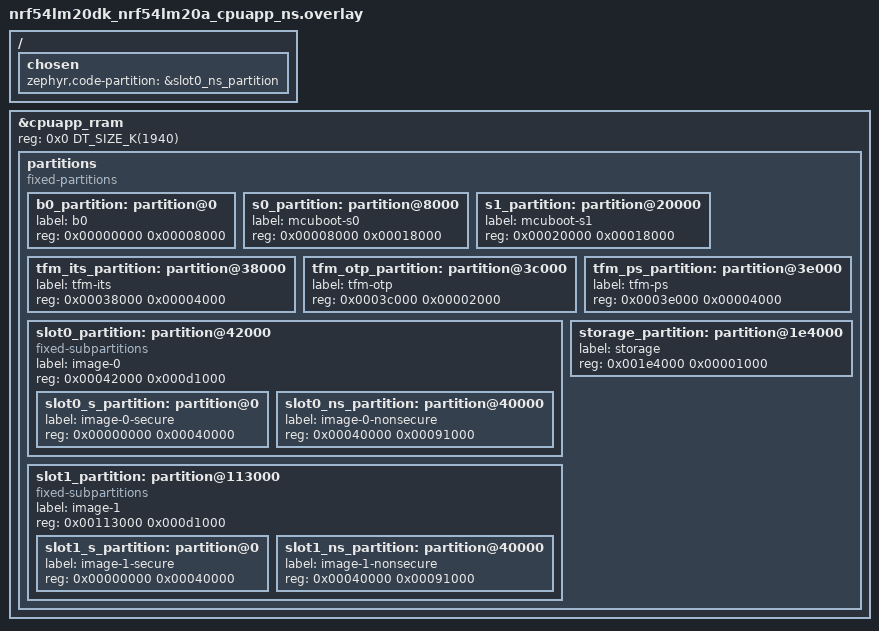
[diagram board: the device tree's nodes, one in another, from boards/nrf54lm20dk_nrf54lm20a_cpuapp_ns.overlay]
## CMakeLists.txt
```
cmake_minimum_required(VERSION 3.20.0)

find_package(Zephyr REQUIRED HINTS $ENV{ZEPHYR_BASE})
project(smp_svr)

target_sources(app PRIVATE src/main.c)
target_sources(app PRIVATE src/bluetooth.c)
```

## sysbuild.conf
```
# Enable an upgradable MCUboot chain:
# NSIB (B0) verifies and boots MCUboot, then MCUboot verifies the application.
SB_CONFIG_PARTITION_MANAGER=n
SB_CONFIG_SECURE_BOOT_APPCORE=y
SB_CONFIG_BOOTLOADER_MCUBOOT=y

# nRF54L/LM devices use Ed25519 for secure boot and MCUboot signatures.
SB_CONFIG_BOOT_SIGNATURE_TYPE_ED25519=y
SB_CONFIG_SECURE_BOOT_SIGNING_KEY_FILE="\${ZEPHYR_MCUBOOT_MODULE_DIR}/root-ed25519.pem"
SB_CONFIG_BOOT_SIGNATURE_KEY_FILE="\${ZEPHYR_MCUBOOT_MODULE_DIR}/root-ed25519.pem"

# The NSIB/B0 verification key is provisioned into KMU by the custom sysbuild
# keyfile generation step in sysbuild/CMakeLists.txt. MCUboot's application
# verification key is compiled into MCUboot to keep provisioning simple.
SB_CONFIG_SECURE_BOOT_MCUBOOT_VERSION="0.0.1+2"
```

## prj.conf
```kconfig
# Minimal BLE SMP DFU application for nRF54LM20A.
# For the /ns target, TF-M is built automatically. Keep the default profile so
# the static DTS layout can provide an aligned secure/non-secure flash layout.
CONFIG_USE_DT_CODE_PARTITION=y

CONFIG_NET_BUF=y
CONFIG_ZCBOR=y
CONFIG_CRC=y
CONFIG_MCUMGR=y
CONFIG_STREAM_FLASH=y
CONFIG_FLASH_MAP=y
CONFIG_FLASH=y

# MCUboot application update support.
CONFIG_BOOTLOADER_MCUBOOT=y
CONFIG_IMG_MANAGER=y
CONFIG_MCUMGR_GRP_IMG=y
CONFIG_MCUMGR_GRP_OS=y

# Application image version used by MCUboot and printed at boot.
CONFIG_MCUBOOT_IMGTOOL_SIGN_VERSION="1.0.2+4"
CONFIG_MCUBOOT_EXTRA_IMGTOOL_ARGS="--slot-size 0xd1000 --hex-addr 0x42000"

CONFIG_BT_DEVICE_NAME="NCS_DFU_LM20A"

# Stack sizes for Bluetooth SMP DFU requests.
CONFIG_SYSTEM_WORKQUEUE_STACK_SIZE=2304
CONFIG_MAIN_STACK_SIZE=2176

# Logging.
CONFIG_LOG=y
CONFIG_MCUBOOT_UTIL_LOG_LEVEL_WRN=y
CONFIG_LOG_MAX_LEVEL=3
```

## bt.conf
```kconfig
CONFIG_BT=y
CONFIG_BT_PERIPHERAL=y
CONFIG_BT_DEVICE_NAME="NCS_DFU_LM20A"

# Large ATT packets improve Bluetooth SMP DFU throughput.
CONFIG_BT_L2CAP_TX_MTU=498
CONFIG_BT_BUF_ACL_RX_SIZE=502
CONFIG_BT_BUF_ACL_TX_SIZE=502
CONFIG_BT_CTLR_DATA_LENGTH_MAX=251
CONFIG_BT_CTLR_PHY_2M=y

# Bluetooth SMP transport.
CONFIG_MCUMGR_TRANSPORT_BT=y
CONFIG_MCUMGR_TRANSPORT_BT_CONN_PARAM_CONTROL=y

# MCUmgr buffer size is optimized to fit one SMP packet divided into five Bluetooth Write Commands,
# transmitted with the maximum possible MTU value: 498 bytes.
CONFIG_MCUMGR_TRANSPORT_BT_REASSEMBLY=y
CONFIG_MCUMGR_TRANSPORT_NETBUF_SIZE=2475
CONFIG_MCUMGR_GRP_OS_MCUMGR_PARAMS=y
CONFIG_MCUMGR_TRANSPORT_WORKQUEUE_STACK_SIZE=4608

# Keep the controller configuration small.
CONFIG_BT_CTLR_LE_PING=n
```

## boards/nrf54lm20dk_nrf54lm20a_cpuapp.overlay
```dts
/*
 * Static DTS partitions for nRF54LM20A with NSIB + upgradable MCUboot.
 */

/delete-node/ &boot_partition;
/delete-node/ &slot0_partition;
/delete-node/ &slot1_partition;
/delete-node/ &storage_partition;

&cpuapp_rram {
	reg = <0x0 DT_SIZE_K(1940)>;

	partitions {
		compatible = "fixed-partitions";
		#address-cells = <1>;
		#size-cells = <1>;

		b0_partition: partition@0 {
			label = "b0";
			reg = <0x00000000 0x00008000>;
		};

		s0_partition: partition@8000 {
			label = "mcuboot-s0";
			reg = <0x00008000 0x00018000>;
		};

		s1_partition: partition@20000 {
			label = "mcuboot-s1";
			reg = <0x00020000 0x00018000>;
		};

		tfm_its_partition: partition@38000 {
			label = "tfm-its";
			reg = <0x00038000 0x00004000>;
		};

		tfm_otp_partition: partition@3c000 {
			label = "tfm-otp";
			reg = <0x0003c000 0x00002000>;
		};

		tfm_ps_partition: partition@3e000 {
			label = "tfm-ps";
			reg = <0x0003e000 0x00004000>;
		};

		slot0_partition: partition@42000 {
			compatible = "fixed-subpartitions";
			label = "image-0";
			reg = <0x00042000 0x000d1000>;
			ranges = <0x0 0x00042000 0x000d1000>;
			#address-cells = <1>;
			#size-cells = <1>;

			slot0_s_partition: partition@0 {
				label = "image-0-secure";
				reg = <0x00000000 0x00040000>;
			};

			slot0_ns_partition: partition@40000 {
				label = "image-0-nonsecure";
				reg = <0x00040000 0x00091000>;
			};
		};

		slot1_partition: partition@113000 {
			compatible = "fixed-subpartitions";
			label = "image-1";
			reg = <0x00113000 0x000d1000>;
			ranges = <0x0 0x00113000 0x000d1000>;
			#address-cells = <1>;
			#size-cells = <1>;

			slot1_s_partition: partition@0 {
				label = "image-1-secure";
				reg = <0x00000000 0x00040000>;
			};

			slot1_ns_partition: partition@40000 {
				label = "image-1-nonsecure";
				reg = <0x00040000 0x00091000>;
			};
		};

		storage_partition: partition@1e4000 {
			label = "storage";
			reg = <0x001e4000 0x00001000>;
		};
	};
};
```

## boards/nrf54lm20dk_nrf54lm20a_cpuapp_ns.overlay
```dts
/*
 * Static DTS partitions for nRF54LM20A TF-M builds with NSIB + upgradable MCUboot.
 */

/delete-node/ &slot0_partition;
/delete-node/ &tfm_ps_partition;
/delete-node/ &tfm_its_partition;
/delete-node/ &tfm_otp_partition;
/delete-node/ &slot0_ns_partition;
/delete-node/ &storage_partition;

&cpuapp_rram {
	reg = <0x0 DT_SIZE_K(1940)>;

	partitions {
		compatible = "fixed-partitions";
		#address-cells = <1>;
		#size-cells = <1>;

		b0_partition: partition@0 {
			label = "b0";
			reg = <0x00000000 0x00008000>;
		};

		s0_partition: partition@8000 {
			label = "mcuboot-s0";
			reg = <0x00008000 0x00018000>;
		};

		s1_partition: partition@20000 {
			label = "mcuboot-s1";
			reg = <0x00020000 0x00018000>;
		};

		tfm_its_partition: partition@38000 {
			label = "tfm-its";
			reg = <0x00038000 0x00004000>;
		};

		tfm_otp_partition: partition@3c000 {
			label = "tfm-otp";
			reg = <0x0003c000 0x00002000>;
		};

		tfm_ps_partition: partition@3e000 {
			label = "tfm-ps";
			reg = <0x0003e000 0x00004000>;
		};

		slot0_partition: partition@42000 {
			compatible = "fixed-subpartitions";
			label = "image-0";
			reg = <0x00042000 0x000d1000>;
			ranges = <0x0 0x00042000 0x000d1000>;
			#address-cells = <1>;
			#size-cells = <1>;

			slot0_s_partition: partition@0 {
				label = "image-0-secure";
				reg = <0x00000000 0x00040000>;
			};

			slot0_ns_partition: partition@40000 {
				label = "image-0-nonsecure";
				reg = <0x00040000 0x00091000>;
			};
		};

		slot1_partition: partition@113000 {
			compatible = "fixed-subpartitions";
			label = "image-1";
			reg = <0x00113000 0x000d1000>;
			ranges = <0x0 0x00113000 0x000d1000>;
			#address-cells = <1>;
			#size-cells = <1>;

			slot1_s_partition: partition@0 {
				label = "image-1-secure";
				reg = <0x00000000 0x00040000>;
			};

			slot1_ns_partition: partition@40000 {
				label = "image-1-nonsecure";
				reg = <0x00040000 0x00091000>;
			};
		};

		storage_partition: partition@1e4000 {
			label = "storage";
			reg = <0x001e4000 0x00001000>;
		};
	};
};

/ {
	chosen {
		zephyr,code-partition = &slot0_ns_partition;
	};
};
```

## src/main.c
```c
/*
 * Copyright (c) 2012-2014 Wind River Systems, Inc.
 * Copyright (c) 2020 Prevas A/S
 *
 * SPDX-License-Identifier: Apache-2.0
 */

#include <zephyr/kernel.h>

#define LOG_LEVEL LOG_LEVEL_DBG
#include <zephyr/logging/log.h>
LOG_MODULE_REGISTER(smp_sample);

#include "common.h"

static void log_bootloader_versions(void)
{
#ifdef CONFIG_MCUBOOT_IMGTOOL_SIGN_VERSION
	LOG_INF("APP image version: %s", CONFIG_MCUBOOT_IMGTOOL_SIGN_VERSION);
#else
	LOG_INF("APP image version: unavailable");
#endif
}

int main(void)
{
	start_smp_bluetooth_adverts();

	/* using __TIME__ ensure that a new binary will be built on every
	 * compile which is convenient when testing firmware upgrade.
	 */
	LOG_INF("build time: " __DATE__ " " __TIME__);
	log_bootloader_versions();

	/* The system work queue handles all incoming mcumgr requests.  Let the
	 * main thread idle while the mcumgr server runs.
	 */
	while (1) {
		k_sleep(K_MSEC(1000));
	}
	return 0;
}
```
